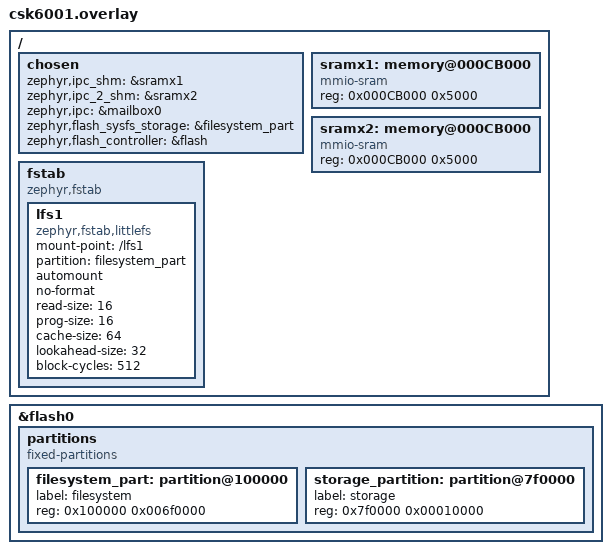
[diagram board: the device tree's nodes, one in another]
/*
 * Copyright (c) 2019 Linaro Limited
 *
 * SPDX-License-Identifier: Apache-2.0
 */
///delete-node/ &storage_partition;

/ {
	chosen {
		/*
		 * shared memory reserved for the inter-processor communication
		 */
		zephyr,ipc_shm = &sramx1;
		zephyr,ipc_2_shm = &sramx2;
		zephyr,ipc = &mailbox0;
		zephyr,flash_sysfs_storage = &filesystem_part;
		zephyr,flash_controller = &flash;
	};

	sramx1:memory@000CB000{
		compatible = "mmio-sram";
		reg = <0x000CB000 0x5000>;
	};

	sramx2:memory@000CB000{
		compatible = "mmio-sram";
		reg = <0x000CB000 0x5000>;
	};
	
	fstab {
		compatible = "zephyr,fstab";
		lfs1: lfs1 {
			compatible = "zephyr,fstab,littlefs";
			mount-point = "/lfs1";
			partition = <&filesystem_part>;
			automount ;
			no-format;
			read-size = <16>;
			prog-size = <16>;
			cache-size = <64>;
			lookahead-size = <32>;
			block-cycles = <512>;
		};
	};

};

 
&flash0 {
	partitions {
		compatible = "fixed-partitions";
		#address-cells = <1>;
		#size-cells = <1>;
		/*
		 * 0x000000-0x0000fffff  = 1MB for code area
		 * 0x100000-0x0007effff  = 6.9375MB for file system
		 * 0x7f0000-0x0007fffff  = 0.0625MB for storage(NVS or easyFlash)
		 */
		filesystem_part: partition@100000 {
			label = "filesystem";
			reg = <0x100000 0x006f0000>;
		};
		/*
		 * Reserve the final 64 KiB for file system partition
		 */
		storage_partition: partition@7f0000 {
			label = "storage";
			reg = <0x7f0000 0x00010000>;
		};


	};
};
